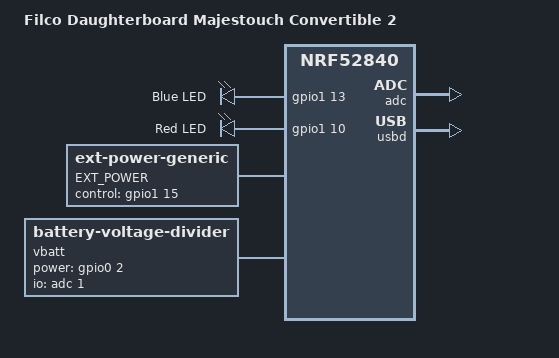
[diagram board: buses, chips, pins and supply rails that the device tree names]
/*
 * Custom daughterboard for the Filco Majestouch Convertible 2.
 * MCU module: Holyiot 18010 (Nordic nRF52840).
 *
 * Copyright (c) 2020 The ZMK Contributors
 * SPDX-License-Identifier: MIT
 */

/dts-v1/;
#include <nordic/nrf52840_qiaa.dtsi>
#include <common/nordic/nrf52840_uf2_boot_mode.dtsi>

/ {
    model = "Filco Daughterboard Majestouch Convertible 2";
    compatible = "karl5275,filco-daughterboard";

    chosen {
        zephyr,code-partition = &code_partition;
        zephyr,sram = &sram0;
        zephyr,flash = &flash0;
        zmk,battery = &vbatt;
    };

    leds: leds {
        compatible = "gpio-leds";
        status = "okay";
        blue_led: led_0 {
            gpios = <&gpio1 13 GPIO_ACTIVE_HIGH>;
            label = "Blue LED";
        };
        red_led: led_1 {
            gpios = <&gpio1 10 GPIO_ACTIVE_HIGH>;
            label = "Red LED";
        };
    };

    // Node name must match original "EXT_POWER" label to preserve user settings.
    EXT_POWER {
        compatible = "zmk,ext-power-generic";
        init-delay-ms = <20>;
        control-gpios = <&gpio1 15 GPIO_ACTIVE_HIGH>;
    };

    vbatt: vbatt {
        compatible = "zmk,battery-voltage-divider";
        io-channels = <&adc 1>;
        output-ohms = <2000000>;
        full-ohms = <(2000000 + 806000)>;
        power-gpios = <&gpio0 2 GPIO_ACTIVE_HIGH>;
    };
};

/* Use the internal DC/DC regulator for lower current draw (battery life). */
&reg1 {
    regulator-initial-mode = <NRF5X_REG_MODE_DCDC>;
};

&adc {
    status = "okay";
};

&gpiote {
    status = "okay";
};

&gpio0 {
    status = "okay";
};

&gpio1 {
    status = "okay";
};

zephyr_udc0: &usbd {
    status = "okay";
};

&flash0 {
    /*
     * For more information, see:
     * http://docs.zephyrproject.org/latest/devices/dts/flash_partitions.html
     */
    partitions {
        compatible = "fixed-partitions";
        #address-cells = <1>;
        #size-cells = <1>;

        sd_partition: partition@0 {
            reg = <0x00000000 0x00026000>;
        };
        code_partition: partition@26000 {
            reg = <0x00026000 0x000c6000>;
        };

        /*
         * The flash starting at 0x000ec000 and ending at
         * 0x000f3fff is reserved for use by the application.
         */

        /*
         * Storage partition will be used by FCB/LittleFS/NVS
         * if enabled.
         */
        storage_partition: partition@ec000 {
            reg = <0x000ec000 0x00008000>;
        };

        boot_partition: partition@f4000 {
            reg = <0x000f4000 0x0000c000>;
        };
    };
};
